# WKUP_j7aen_wkup_ctrl_mmr0_CFG0 register map
Vendor: Texas Instruments
Peripheral module from a debugger description file (folder J722S).
Registers are 32-bit, read-write, reset 0x0 unless marked. A register's access mark holds for its fields unless they carry their own. Offsets are as the file gives them; lines under a group give offsets from that group; [hi:lo] are bit positions; {n}, {i} and the like mark numbered series; 'fields as' and 'values as' point back to an identical list; <NAME> marks a mode.

## WKUP_j7aen_wkup_ctrl_mmr0_CFG0 (part 1 of 3)
{0x7100+4i} CFG0_CLAIMREG_P1_R{i} (i=0..14)
  [31:0] CLAIMREG_P1_R{i} — Claim bits for Partition 1
0x8010 CFG0_WKUP_CLKSEL
  [0] WKUP_CLKSEL_CLK_SEL — Selects Clock Source for Wakeup Domain (Device Manager and Peripherals) Field values (others are reserved): 1'b0 - CPU_MAIN_PLL15_HSDIV2_CLKOUT__PERIPHERALS_ MAIN_PLL15_HSDIV0_CLKOUT undefined - undefined 1'b1 - CPU_AND_PERIPHERALS_MCU_PLL0_HSDIV0_CLKOUT
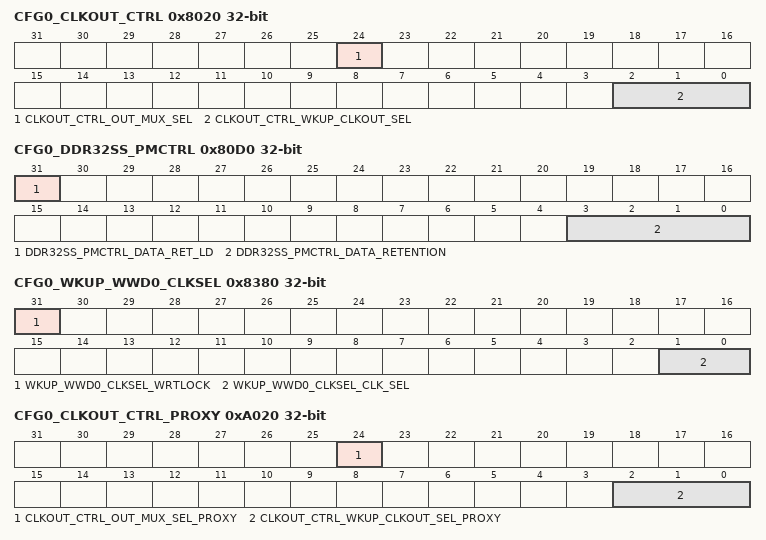
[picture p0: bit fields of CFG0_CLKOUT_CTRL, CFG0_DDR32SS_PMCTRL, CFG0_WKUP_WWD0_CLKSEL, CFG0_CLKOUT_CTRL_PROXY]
0x8020 CFG0_CLKOUT_CTRL
  [24] CLKOUT_CTRL_OUT_MUX_SEL — WKUP CLKOUT (Pin) pin output mux selection. HFOSC0_CLK is a direct output from the HFOSC0 Field values (others are reserved): 1'b0 - CLK_DIV_OUT 1'b1 - HFOSC0_CLK (clk_sel must be DRIVE_LOW)
  [2:0] CLKOUT_CTRL_WKUP_CLKOUT_SEL — Controls WKUP CLKOUT MUX for WKUP_CLKOUT0 Pin Field values (others are reserved): undefined - undefined 3'b000 - DRIVE_LOW 3'b001 - LFOSC0_CLKOUT 3'b010 - MAIN_PLL0_HSDIV2_CLKOUT 3'b011 - MAIN_PLL1_HSDIV2_CLKOUT 3'b100 - MAIN_PLL2_HSDIV9_CLKOUT 3'b101 - DEVICE_CLKOUT_32K 3'b110 - CLK_12M_RC 3'b111 - HFOSC0_CLKOUT
0x8030 CFG0_WKUP_GTC_CLKSEL reset 0x1
  [2:0] WKUP_GTC_CLKSEL_CLK_SEL — Selects the GTC timebase clock source Field values (others are reserved): 3'b000 - MAIN_PLL2_HSDIV5_CLKOUT 3'b001 - MAIN_PLL0_HSDIV6_CLKOUT 3'b010 - CP_GEMAC_CPTS0_RFT_CLK (Pin) 3'b011 - Reserved '0' 3'b100 - MCU_EXT_REFCLK0 (Pin) 3'b101 - EXT_REFCLK1 (Pin) 3'b110 - MCU_SYSCLK0_DIV2 undefined - undefined 3'b111 - MAIN_SYSCLK0
0x803C CFG0_EFUSE_CLKSEL
  [0] EFUSE_CLKSEL_CLK_SEL — Selects the clock source Field values (others are reserved): 1'b0 - HFOSC0_CLKOUT 1'b1 - MAIN_SYSCLK0/16
0x80D0 CFG0_DDR32SS_PMCTRL
  [31] DDR32SS_PMCTRL_DATA_RET_LD — Controls latching of the retention value Field values (others are reserved): 1'b0 - LATCH_CLOSED 1'b1 - LATCH_OPEN
  [3:0] DDR32SS_PMCTRL_DATA_RETENTION — DDR32SS Retention: This is a fault tolerant bit field 0x06 Asserts DDRSS 'data_retention' which will Hi-Z most of the phy output pins except for CKE/RESET# All others (Default 0) : data_retention is deasserted for normal DDR32SS Operation Field values (others are reserved): 4'b0000 - RETENTION_DEACTIVATED 4'b0110 - RETENTION_ACTIVATED
0x8190 CFG0_USB0_CLKSEL
  [0] USB0_CLKSEL_REFCLK_SEL — Selects the clock source for the USB0 ref_clk. Field values (others are reserved): 1'b0 - HFOSC0_CLKOUT 1'b1 - MAIN_PLL0_HSDIV8_CLKOUT
0x8194 CFG0_USB1_CLKSEL
  [0] USB1_CLKSEL_REFCLK_SEL — Selects the clock source for the USB1 ref_clk. Field values (others are reserved): 1'b0 - HFOSC0_CLKOUT 1'b1 - MAIN_PLL0_HSDIV8_CLKOUT
0x81B0 CFG0_WKUP_TIMER0_CLKSEL
  [2:0] WKUP_TIMER0_CLKSEL_CLK_SEL — Timer functional clock input select mux control Field values (others are reserved): 3'b000 - HFOSC0_CLKOUT 3'b001 - DM_CLK/2 undefined - undefined 3'b010 - CLK_12M_RC 3'b011 - MCU_PLL0_HSDIV5_CLKOUT 3'b100 - MCU_EXT_REFCLK0 (Pin) 3'b101 - DEVICE_CLKOUT_32K 3'b110 - CPSW0_CPTS_GENF0 3'b111 - CLK_32K_RC
0x81B4 CFG0_WKUP_TIMER1_CLKSEL
  [2:0] WKUP_TIMER1_CLKSEL_CLK_SEL — Timer functional clock input select mux control Field values (others are reserved): 3'b000 - HFOSC0_CLKOUT 3'b001 - DM_CLK/2 undefined - undefined 3'b010 - CLK_12M_RC 3'b011 - MCU_PLL0_HSDIV5_CLKOUT 3'b100 - MCU_EXT_REFCLK0 (Pin) 3'b101 - DEVICE_CLKOUT_32K 3'b110 - CPSW0_CPTS_GENF0 3'b111 - CLK_32K_RC
0x8340 CFG0_WKUP_WWD0_CTRL
  [3:0] WKUP_WWD0_CTRL_WWD_STOP — Controls Clocks to the WWD Watchdog Counter Field values (others are reserved): 4'b0000 - WWD Counter Running 4'b1010 - WWD Counter Stopped
0x8380 CFG0_WKUP_WWD0_CLKSEL
  [31] WKUP_WWD0_CLKSEL_WRTLOCK — When set, locks WKUP_WWD0_CLKSEL from further writes until the next module reset. Field values (others are reserved): 1'b0 - UNLOCKED 1'b1 - LOCKED
  [1:0] WKUP_WWD0_CLKSEL_CLK_SEL — Windowed watchdog timer functional clock input select mux control Field values (others are reserved): 2'b00 - HFOSC0_CLKOUT 2'b01 - DEVICE_CLKOUT_32K 2'b10 - CLK_12M_RC 2'b11 - CLK_32K
0x8600 CFG0_WKUP_RTC_CLKSEL
  [0] WKUP_RTC_CLKSEL_CLK_SEL — Selects the source of the RTC functional clock Field values (others are reserved): 1'b0 - DEVICE_CLKOUT_32K 1'b1 - CLK_32K_RC
{0x9100+4i} CFG0_CLAIMREG_P2_R{i}_READONLY ro (i=0..12)
  [31:0] CLAIMREG_P2_R{i}_READONLY — Claim bits for Partition 2
0xA010 CFG0_WKUP_CLKSEL_PROXY
  [0] WKUP_CLKSEL_CLK_SEL_PROXY — Selects Clock Source for Wakeup Domain (Device Manager and Peripherals) Field values (others are reserved): 1'b0 - CPU_MAIN_PLL15_HSDIV2_CLKOUT__PERIPHERALS_ MAIN_PLL15_HSDIV0_CLKOUT undefined - undefined 1'b1 - CPU_AND_PERIPHERALS_MCU_PLL0_HSDIV0_CLKOUT
0xA020 CFG0_CLKOUT_CTRL_PROXY
  [24] CLKOUT_CTRL_OUT_MUX_SEL_PROXY — WKUP CLKOUT (Pin) pin output mux selection. HFOSC0_CLK is a direct output from the HFOSC0 Field values (others are reserved): 1'b0 - CLK_DIV_OUT 1'b1 - HFOSC0_CLK (clk_sel must be DRIVE_LOW)
  [2:0] CLKOUT_CTRL_WKUP_CLKOUT_SEL_PROXY — Controls WKUP CLKOUT MUX for WKUP_CLKOUT0 Pin Field values (others are reserved): undefined - undefined 3'b000 - DRIVE_LOW 3'b001 - LFOSC0_CLKOUT 3'b010 - MAIN_PLL0_HSDIV2_CLKOUT 3'b011 - MAIN_PLL1_HSDIV2_CLKOUT 3'b100 - MAIN_PLL2_HSDIV9_CLKOUT 3'b101 - DEVICE_CLKOUT_32K 3'b110 - CLK_12M_RC 3'b111 - HFOSC0_CLKOUT
0xA030 CFG0_WKUP_GTC_CLKSEL_PROXY reset 0x1
  [2:0] WKUP_GTC_CLKSEL_CLK_SEL_PROXY — Selects the GTC timebase clock source Field values (others are reserved): 3'b000 - MAIN_PLL2_HSDIV5_CLKOUT 3'b001 - MAIN_PLL0_HSDIV6_CLKOUT 3'b010 - CP_GEMAC_CPTS0_RFT_CLK (Pin) 3'b011 - Reserved '0' 3'b100 - MCU_EXT_REFCLK0 (Pin) 3'b101 - EXT_REFCLK1 (Pin) 3'b110 - MCU_SYSCLK0_DIV2 undefined - undefined 3'b111 - MAIN_SYSCLK0
0xA03C CFG0_EFUSE_CLKSEL_PROXY
  [0] EFUSE_CLKSEL_CLK_SEL_PROXY — Selects the clock source Field values (others are reserved): 1'b0 - HFOSC0_CLKOUT 1'b1 - MAIN_SYSCLK0/16
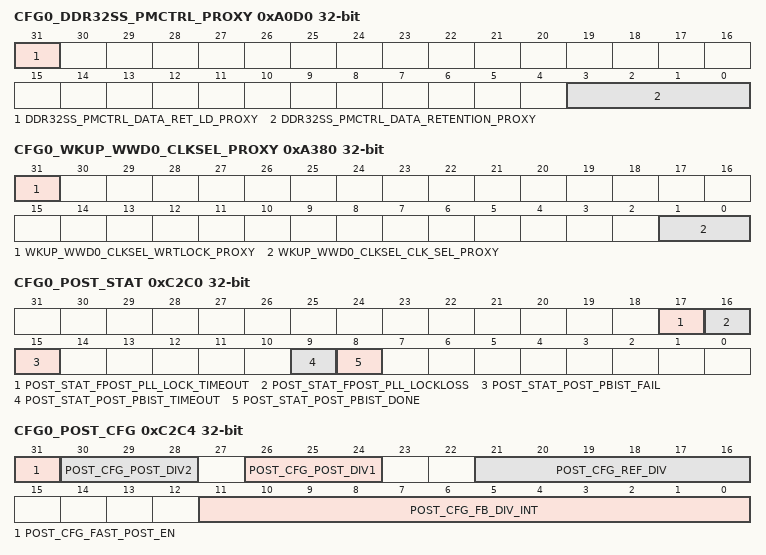
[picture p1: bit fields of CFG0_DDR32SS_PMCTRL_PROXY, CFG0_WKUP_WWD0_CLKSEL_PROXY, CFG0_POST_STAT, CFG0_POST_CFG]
0xA0D0 CFG0_DDR32SS_PMCTRL_PROXY
  [31] DDR32SS_PMCTRL_DATA_RET_LD_PROXY — Controls latching of the retention value Field values (others are reserved): 1'b0 - LATCH_CLOSED 1'b1 - LATCH_OPEN
  [3:0] DDR32SS_PMCTRL_DATA_RETENTION_PROXY — DDR32SS Retention: This is a fault tolerant bit field 0x06 Asserts DDRSS 'data_retention' which will Hi-Z most of the phy output pins except for CKE/RESET# All others (Default 0) : data_retention is deasserted for normal DDR32SS Operation Field values (others are reserved): 4'b0000 - RETENTION_DEACTIVATED 4'b0110 - RETENTION_ACTIVATED
0xA190 CFG0_USB0_CLKSEL_PROXY
  [0] USB0_CLKSEL_REFCLK_SEL_PROXY — Selects the clock source for the USB0 ref_clk. Field values (others are reserved): 1'b0 - HFOSC0_CLKOUT 1'b1 - MAIN_PLL0_HSDIV8_CLKOUT
0xA194 CFG0_USB1_CLKSEL_PROXY
  [0] USB1_CLKSEL_REFCLK_SEL_PROXY — Selects the clock source for the USB1 ref_clk. Field values (others are reserved): 1'b0 - HFOSC0_CLKOUT 1'b1 - MAIN_PLL0_HSDIV8_CLKOUT
0xA1B0 CFG0_WKUP_TIMER0_CLKSEL_PROXY
  [2:0] WKUP_TIMER0_CLKSEL_CLK_SEL_PROXY — Timer functional clock input select mux control Field values (others are reserved): 3'b000 - HFOSC0_CLKOUT 3'b001 - DM_CLK/2 undefined - undefined 3'b010 - CLK_12M_RC 3'b011 - MCU_PLL0_HSDIV5_CLKOUT 3'b100 - MCU_EXT_REFCLK0 (Pin) 3'b101 - DEVICE_CLKOUT_32K 3'b110 - CPSW0_CPTS_GENF0 3'b111 - CLK_32K_RC
0xA1B4 CFG0_WKUP_TIMER1_CLKSEL_PROXY
  [2:0] WKUP_TIMER1_CLKSEL_CLK_SEL_PROXY — Timer functional clock input select mux control Field values (others are reserved): 3'b000 - HFOSC0_CLKOUT 3'b001 - DM_CLK/2 undefined - undefined 3'b010 - CLK_12M_RC 3'b011 - MCU_PLL0_HSDIV5_CLKOUT 3'b100 - MCU_EXT_REFCLK0 (Pin) 3'b101 - DEVICE_CLKOUT_32K 3'b110 - CPSW0_CPTS_GENF0 3'b111 - CLK_32K_RC
0xA340 CFG0_WKUP_WWD0_CTRL_PROXY
  [3:0] WKUP_WWD0_CTRL_WWD_STOP_PROXY — Controls Clocks to the WWD Watchdog Counter Field values (others are reserved): 4'b0000 - WWD Counter Running 4'b1010 - WWD Counter Stopped
0xA380 CFG0_WKUP_WWD0_CLKSEL_PROXY
  [31] WKUP_WWD0_CLKSEL_WRTLOCK_PROXY — When set, locks WKUP_WWD0_CLKSEL from further writes until the next module reset. Field values (others are reserved): 1'b0 - UNLOCKED 1'b1 - LOCKED
  [1:0] WKUP_WWD0_CLKSEL_CLK_SEL_PROXY — Windowed watchdog timer functional clock input select mux control Field values (others are reserved): 2'b00 - HFOSC0_CLKOUT 2'b01 - DEVICE_CLKOUT_32K 2'b10 - CLK_12M_RC 2'b11 - CLK_32K
0xA600 CFG0_WKUP_RTC_CLKSEL_PROXY
  [0] WKUP_RTC_CLKSEL_CLK_SEL_PROXY — Selects the source of the RTC functional clock Field values (others are reserved): 1'b0 - DEVICE_CLKOUT_32K 1'b1 - CLK_32K_RC
{0xB100+4i} CFG0_CLAIMREG_P2_R{i} (i=0..12)
  [31:0] CLAIMREG_P2_R{i} — Claim bits for Partition 2
0xC2C0 CFG0_POST_STAT ro
  [17] POST_STAT_FPOST_PLL_LOCK_TIMEOUT — Differentiates between Fast POST and Slow POST. Fast POST is initiated after the PLL locks using the settings in the POST_CFG MMR. Otherwise, if the PLL lock times out, Slow POST is initated at the PLL reference clock rate. Field values (others are reserved): 1'b0 - FAST_POST 1'b1 - SLOW_POST
  [16] POST_STAT_FPOST_PLL_LOCKLOSS — Indicates that POST exited with a PLL Lockloss Error Field values (others are reserved): 1'b0 - UNKNOWN 1'b1 - EXITED_ON_LOCK_LOSS
  [15] POST_STAT_POST_PBIST_FAIL — POST PBIST failed Field values (others are reserved): 1'b0 - UNKNOWN 1'b1 - FAIL
  [9] POST_STAT_POST_PBIST_TIMEOUT — POST PBIST timed out Field values (others are reserved): 1'b0 - UNKNOWN 1'b1 - TIMEOUT
  [8] POST_STAT_POST_PBIST_DONE — POST PBIST done Field values (others are reserved): 1'b0 - UNKNOWN 1'b1 - DONE
0xC2C4 CFG0_POST_CFG ro
  [31] POST_CFG_FAST_POST_EN — Activate Fast POST mode Field values (others are reserved): 1'b0 - DEACTIVATE 1'b1 - ACTIVATE
  [30:28] POST_CFG_POST_DIV2 — Fast POST PLL secondary post-divider value, must be less than or equal to post_div1. Field values (others are reserved): 3'b000 - UNSUPPORTED 3'b001 - DIV1 3'b010 - DIV2 3'b011 - DIV3 3'b100 - DIV4 3'b101 - DIV5 3'b110 - DIV6 3'b111 - DIV7
  [26:24] POST_CFG_POST_DIV1 — Fast POST PLL primary post-divider value, must be greater than or equal to post_div2. Field values (others are reserved): 3'b000 - UNSUPPORTED 3'b001 - DIV1 3'b010 - DIV2 3'b011 - DIV3 3'b100 - DIV4 3'b101 - DIV5 3'b110 - DIV6 3'b111 - DIV7
  [21:16] POST_CFG_REF_DIV — Fast POST PLL reference clock pre-divider value. Field values (others are reserved): 6'b000000 - UNSUPPORTED 6'b000001 - DIV1 6'b000010 - DIV2 6'b000011 - DIV3 6'b000100 - DIV4 6'b000101 - DIV5 6'b000110 - DIV6 6'b000111 - DIV7 6'b001000 - DIV8 6'b001001 - DIV9 6'b001010 - DIV10 6'b001011 - DIV11 6'b001100 - DIV12 6'b001101 - DIV13 6'b001110 - DIV14 6'b001111 - DIV15 6'b010000 - DIV16 6'b010001 - DIV17 6'b010010 - DIV18 6'b010011 - DIV19 6'b010100 - DIV20 6'b010101 - DIV21 6'b010110 - DIV22 6'b010111 - DIV23 6'b011000 - DIV24 6'b011001 - DIV25 6'b011010 - DIV26 6'b011011 - DIV27 6'b011100 - DIV28 6'b011101 - DIV29 6'b011110 - DIV30 6'b011111 - DIV31 6'b100000 - DIV32 6'b100001 - DIV33 6'b100010 - DIV34 6'b100011 - DIV35 6'b100100 - DIV36 6'b100101 - DIV37 6'b100110 - DIV38 6'b100111 - DIV39 6'b101000 - DIV40 6'b101001 - DIV41 6'b101010 - DIV42 6'b101011 - DIV43 6'b101100 - DIV44 6'b101101 - DIV45 6'b101110 - DIV46 6'b101111 - DIV47 6'b110000 - DIV48 6'b110001 - DIV49 6'b110010 - DIV50 6'b110011 - DIV51 6'b110100 - DIV52 6'b110101 - DIV53 6'b110110 - DIV54 6'b110111 - DIV55 6'b111000 - DIV56 6'b111001 - DIV57 6'b111010 - DIV58 6'b111011 - DIV59 6'b111100 - DIV60 6'b111101 - DIV61 6'b111110 - DIV62 6'b111111 - DIV63
  [11:0] POST_CFG_FB_DIV_INT — Fast POST PLL feedback divider (integer portion) value. In Integer mode values of 16 - 3200 (decimal) are supported.
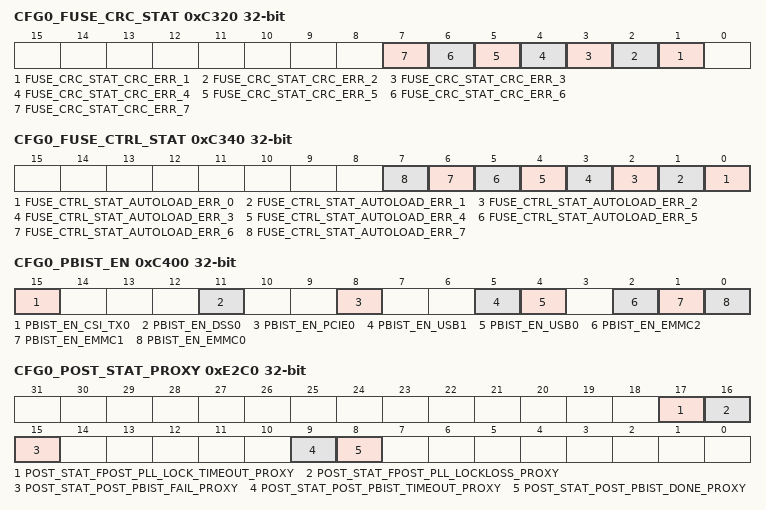
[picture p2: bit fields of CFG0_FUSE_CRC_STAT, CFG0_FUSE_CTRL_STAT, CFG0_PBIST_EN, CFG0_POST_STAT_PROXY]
0xC320 CFG0_FUSE_CRC_STAT ro
  [n] FUSE_CRC_STAT_CRC_ERR_{n} (n=1..7) — Indicates eFuse CRC error on chain {n} Field values (others are reserved): 1'b0 - NO_ERROR 1'b1 - ERROR
0xC340 CFG0_FUSE_CTRL_STAT ro
  [n] FUSE_CTRL_STAT_AUTOLOAD_ERR_{n} (n=0..7) — Autoload Error Status Chain {n} Field values (others are reserved): 1'b0 - NO_ERROR 1'b1 - ERROR
0xC400 CFG0_PBIST_EN
  [15] PBIST_EN_CSI_TX0 — Activates PBIST Access to CSI-TX0 Memories Field values (others are reserved): 1'b0 - DEACTIVATE 1'b1 - ACTIVATE
  [11] PBIST_EN_DSS0 — Activates PBIST Access to DSS0 Memories Field values (others are reserved): 1'b0 - DEACTIVATE 1'b1 - ACTIVATE
  [8] PBIST_EN_PCIE0 — Activates PBIST Access to PCIE0 Memories Field values (others are reserved): 1'b0 - DEACTIVATE 1'b1 - ACTIVATE
  [5] PBIST_EN_USB1 — Activates PBIST Access to USB1 Memories Field values (others are reserved): 1'b0 - DEACTIVATE 1'b1 - ACTIVATE
  [4] PBIST_EN_USB0 — Activates PBIST Access to USB0 Memories Field values (others are reserved): 1'b0 - DEACTIVATE 1'b1 - ACTIVATE
  [2] PBIST_EN_EMMC2 — Activates PBIST Access to MMC2 Memories Field values (others are reserved): 1'b0 - DEACTIVATE 1'b1 - ACTIVATE
  [1] PBIST_EN_EMMC1 — Activates PBIST Access to MMC1 Memories Field values (others are reserved): 1'b0 - DEACTIVATE 1'b1 - ACTIVATE
  [0] PBIST_EN_EMMC0 — Activates PBIST Access to MMC0 Memories Field values (others are reserved): 1'b0 - DEACTIVATE 1'b1 - ACTIVATE
{0xD100+4i} CFG0_CLAIMREG_P3_R{i}_READONLY ro (i=0..8)
  [31:0] CLAIMREG_P3_R{i}_READONLY — Claim bits for Partition 3
0xE2C0 CFG0_POST_STAT_PROXY ro
  [17] POST_STAT_FPOST_PLL_LOCK_TIMEOUT_PROXY — Differentiates between Fast POST and Slow POST. Fast POST is initiated after the PLL locks using the settings in the POST_CFG MMR. Otherwise, if the PLL lock times out, Slow POST is initated at the PLL reference clock rate. Field values (others are reserved): 1'b0 - FAST_POST 1'b1 - SLOW_POST
  [16] POST_STAT_FPOST_PLL_LOCKLOSS_PROXY — Indicates that POST exited with a PLL Lockloss Error Field values (others are reserved): 1'b0 - UNKNOWN 1'b1 - EXITED_ON_LOCK_LOSS
  [15] POST_STAT_POST_PBIST_FAIL_PROXY — POST PBIST failed Field values (others are reserved): 1'b0 - UNKNOWN 1'b1 - FAIL
  [9] POST_STAT_POST_PBIST_TIMEOUT_PROXY — POST PBIST timed out Field values (others are reserved): 1'b0 - UNKNOWN 1'b1 - TIMEOUT
  [8] POST_STAT_POST_PBIST_DONE_PROXY — POST PBIST done Field values (others are reserved): 1'b0 - UNKNOWN 1'b1 - DONE
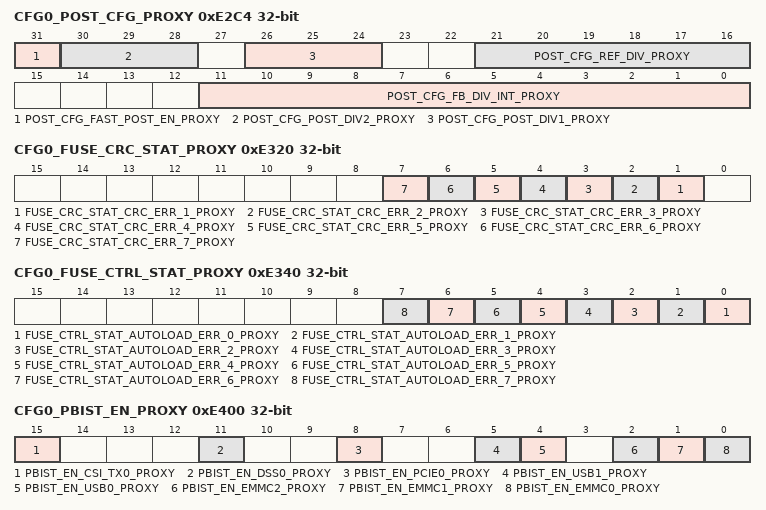
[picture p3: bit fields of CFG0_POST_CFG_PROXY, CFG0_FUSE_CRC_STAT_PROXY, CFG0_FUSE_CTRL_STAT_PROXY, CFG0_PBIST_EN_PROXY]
0xE2C4 CFG0_POST_CFG_PROXY ro
  [31] POST_CFG_FAST_POST_EN_PROXY — Activate Fast POST mode Field values (others are reserved): 1'b0 - DEACTIVATE 1'b1 - ACTIVATE
  [30:28] POST_CFG_POST_DIV2_PROXY — Fast POST PLL secondary post-divider value, must be less than or equal to post_div1. Field values (others are reserved): 3'b000 - UNSUPPORTED 3'b001 - DIV1 3'b010 - DIV2 3'b011 - DIV3 3'b100 - DIV4 3'b101 - DIV5 3'b110 - DIV6 3'b111 - DIV7
  [26:24] POST_CFG_POST_DIV1_PROXY — Fast POST PLL primary post-divider value, must be greater than or equal to post_div2. Field values (others are reserved): 3'b000 - UNSUPPORTED 3'b001 - DIV1 3'b010 - DIV2 3'b011 - DIV3 3'b100 - DIV4 3'b101 - DIV5 3'b110 - DIV6 3'b111 - DIV7
  [21:16] POST_CFG_REF_DIV_PROXY — Fast POST PLL reference clock pre-divider value. Field values (others are reserved): 6'b000000 - UNSUPPORTED 6'b000001 - DIV1 6'b000010 - DIV2 6'b000011 - DIV3 6'b000100 - DIV4 6'b000101 - DIV5 6'b000110 - DIV6 6'b000111 - DIV7 6'b001000 - DIV8 6'b001001 - DIV9 6'b001010 - DIV10 6'b001011 - DIV11 6'b001100 - DIV12 6'b001101 - DIV13 6'b001110 - DIV14 6'b001111 - DIV15 6'b010000 - DIV16 6'b010001 - DIV17 6'b010010 - DIV18 6'b010011 - DIV19 6'b010100 - DIV20 6'b010101 - DIV21 6'b010110 - DIV22 6'b010111 - DIV23 6'b011000 - DIV24 6'b011001 - DIV25 6'b011010 - DIV26 6'b011011 - DIV27 6'b011100 - DIV28 6'b011101 - DIV29 6'b011110 - DIV30 6'b011111 - DIV31 6'b100000 - DIV32 6'b100001 - DIV33 6'b100010 - DIV34 6'b100011 - DIV35 6'b100100 - DIV36 6'b100101 - DIV37 6'b100110 - DIV38 6'b100111 - DIV39 6'b101000 - DIV40 6'b101001 - DIV41 6'b101010 - DIV42 6'b101011 - DIV43 6'b101100 - DIV44 6'b101101 - DIV45 6'b101110 - DIV46 6'b101111 - DIV47 6'b110000 - DIV48 6'b110001 - DIV49 6'b110010 - DIV50 6'b110011 - DIV51 6'b110100 - DIV52 6'b110101 - DIV53 6'b110110 - DIV54 6'b110111 - DIV55 6'b111000 - DIV56 6'b111001 - DIV57 6'b111010 - DIV58 6'b111011 - DIV59 6'b111100 - DIV60 6'b111101 - DIV61 6'b111110 - DIV62 6'b111111 - DIV63
  [11:0] POST_CFG_FB_DIV_INT_PROXY — Fast POST PLL feedback divider (integer portion) value. In Integer mode values of 16 - 3200 (decimal) are supported.
0xE320 CFG0_FUSE_CRC_STAT_PROXY ro
  [n] FUSE_CRC_STAT_CRC_ERR_{n}_PROXY (n=1..7) — Indicates eFuse CRC error on chain {n} Field values (others are reserved): 1'b0 - NO_ERROR 1'b1 - ERROR
0xE340 CFG0_FUSE_CTRL_STAT_PROXY ro
  [n] FUSE_CTRL_STAT_AUTOLOAD_ERR_{n}_PROXY (n=0..7) — Autoload Error Status Chain {n} Field values (others are reserved): 1'b0 - NO_ERROR 1'b1 - ERROR
0xE400 CFG0_PBIST_EN_PROXY
  [15] PBIST_EN_CSI_TX0_PROXY — Activates PBIST Access to CSI-TX0 Memories Field values (others are reserved): 1'b0 - DEACTIVATE 1'b1 - ACTIVATE
  [11] PBIST_EN_DSS0_PROXY — Activates PBIST Access to DSS0 Memories Field values (others are reserved): 1'b0 - DEACTIVATE 1'b1 - ACTIVATE
  [8] PBIST_EN_PCIE0_PROXY — Activates PBIST Access to PCIE0 Memories Field values (others are reserved): 1'b0 - DEACTIVATE 1'b1 - ACTIVATE
  [5] PBIST_EN_USB1_PROXY — Activates PBIST Access to USB1 Memories Field values (others are reserved): 1'b0 - DEACTIVATE 1'b1 - ACTIVATE
  [4] PBIST_EN_USB0_PROXY — Activates PBIST Access to USB0 Memories Field values (others are reserved): 1'b0 - DEACTIVATE 1'b1 - ACTIVATE
  [2] PBIST_EN_EMMC2_PROXY — Activates PBIST Access to MMC2 Memories Field values (others are reserved): 1'b0 - DEACTIVATE 1'b1 - ACTIVATE
  [1] PBIST_EN_EMMC1_PROXY — Activates PBIST Access to MMC1 Memories Field values (others are reserved): 1'b0 - DEACTIVATE 1'b1 - ACTIVATE
  [0] PBIST_EN_EMMC0_PROXY — Activates PBIST Access to MMC0 Memories Field values (others are reserved): 1'b0 - DEACTIVATE 1'b1 - ACTIVATE
{0xF100+4i} CFG0_CLAIMREG_P3_R{i} (i=0..8)
  [31:0] CLAIMREG_P3_R{i} — Claim bits for Partition 3
{0x11100+4i} CFG0_CLAIMREG_P4_R{i}_READONLY ro (i=0..8)
  [31:0] CLAIMREG_P4_R{i}_READONLY — Claim bits for Partition 4
{0x13100+4i} CFG0_CLAIMREG_P4_R{i} (i=0..8)
  [31:0] CLAIMREG_P4_R{i} — Claim bits for Partition 4
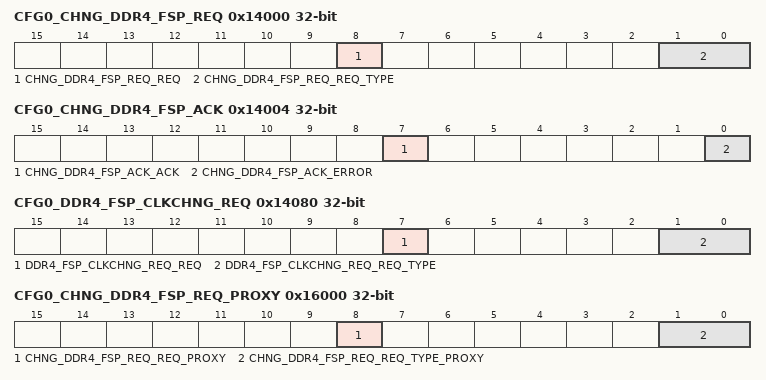
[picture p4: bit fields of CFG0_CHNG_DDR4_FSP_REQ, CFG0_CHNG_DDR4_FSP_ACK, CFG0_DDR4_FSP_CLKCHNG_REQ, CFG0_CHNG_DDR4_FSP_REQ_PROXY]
0x14000 CFG0_CHNG_DDR4_FSP_REQ
  [8] CHNG_DDR4_FSP_REQ_REQ — Initiate FSP frequency change Field values (others are reserved): 1'b0 - INACTIVE 1'b1 - ACTIVE
  [1:0] CHNG_DDR4_FSP_REQ_REQ_TYPE — Frequency request type - Desired Frequency Set Point after switch. Field values (others are reserved): 2'b00 - FSP0 2'b01 - FSP1 2'b10 - FSP2 2'b11 - FSP3
0x14004 CFG0_CHNG_DDR4_FSP_ACK ro
  [7] CHNG_DDR4_FSP_ACK_ACK — Frequency change acknowledge. This bit is only valid when CHNG_DDR4_FSP_REQ_req is active Indication from the DDR Controller that the Frequency Set Point change operation is complete Field values (others are reserved): 1'b0 - IN_PROGRESS 1'b1 - COMPLETE
  [0] CHNG_DDR4_FSP_ACK_ERROR — Frequency change error This bit is only valid when CHNG_DDR4_FSP_REQ_req is active. Field values (others are reserved): 1'b0 - SUCCESS 1'b1 - ERROR
0x14080 CFG0_DDR4_FSP_CLKCHNG_REQ ro
  [7] DDR4_FSP_CLKCHNG_REQ_REQ — DDR Controller FSP clock change request Indicates that the DDR controller needs the DDR clock changed to the frequency set point indicated by the req_type field. This bit is cleared when the DDR4_FSP_CLKCHNG_ACK_ack bit is set. Field values (others are reserved): 1'b0 - INACTIVE 1'b1 - ACTIVE
  [1:0] DDR4_FSP_CLKCHNG_REQ_REQ_TYPE — Frequency request type - Desired Frequency Set Point after switch. Field values (others are reserved): 2'b00 - FSP0 2'b01 - FSP1 2'b10 - FSP2 2'b11 - FSP3
0x140C0 CFG0_DDR4_FSP_CLKCHNG_ACK
  [0] DDR4_FSP_CLKCHNG_ACK_ACK — DDR FSP clock change ackowledge This bit should be set once the DDR clock has been sucessfully changed to the value requested by DDR4_FSP_CLKCHNG_REQ_req_type. Setting this bit will clear the DDR4_FSP_CLKCHNG_REQ_req bit and the associated change request interrupt. Field values (others are reserved): 1'b0 - UNKNOWN (not complete, or not in progress) 1'b1 - COMPLETE
0x15100 CFG0_CLAIMREG_P5_R0_READONLY ro
  [31:0] CLAIMREG_P5_R0_READONLY — Claim bits for Partition 5
0x15104 CFG0_CLAIMREG_P5_R1_READONLY ro
  [31:0] CLAIMREG_P5_R1_READONLY — Claim bits for Partition 5
0x16000 CFG0_CHNG_DDR4_FSP_REQ_PROXY
  [8] CHNG_DDR4_FSP_REQ_REQ_PROXY — Initiate FSP frequency change Field values (others are reserved): 1'b0 - INACTIVE 1'b1 - ACTIVE
  [1:0] CHNG_DDR4_FSP_REQ_REQ_TYPE_PROXY — Frequency request type - Desired Frequency Set Point after switch. Field values (others are reserved): 2'b00 - FSP0 2'b01 - FSP1 2'b10 - FSP2 2'b11 - FSP3
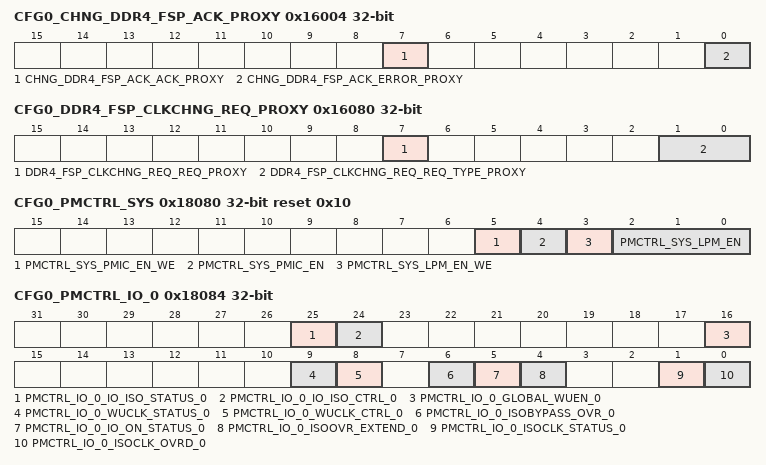
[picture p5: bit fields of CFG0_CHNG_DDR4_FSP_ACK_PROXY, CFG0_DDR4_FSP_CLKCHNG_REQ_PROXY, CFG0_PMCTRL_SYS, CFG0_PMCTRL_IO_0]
0x16004 CFG0_CHNG_DDR4_FSP_ACK_PROXY ro
  [7] CHNG_DDR4_FSP_ACK_ACK_PROXY — Frequency change acknowledge. This bit is only valid when CHNG_DDR4_FSP_REQ_req is active Indication from the DDR Controller that the Frequency Set Point change operation is complete Field values (others are reserved): 1'b0 - IN_PROGRESS 1'b1 - COMPLETE
  [0] CHNG_DDR4_FSP_ACK_ERROR_PROXY — Frequency change error This bit is only valid when CHNG_DDR4_FSP_REQ_req is active. Field values (others are reserved): 1'b0 - SUCCESS 1'b1 - ERROR
0x16080 CFG0_DDR4_FSP_CLKCHNG_REQ_PROXY ro
  [7] DDR4_FSP_CLKCHNG_REQ_REQ_PROXY — DDR Controller FSP clock change request Indicates that the DDR controller needs the DDR clock changed to the frequency set point indicated by the req_type field. This bit is cleared when the DDR4_FSP_CLKCHNG_ACK_ack bit is set. Field values (others are reserved): 1'b0 - INACTIVE 1'b1 - ACTIVE
  [1:0] DDR4_FSP_CLKCHNG_REQ_REQ_TYPE_PROXY — Frequency request type - Desired Frequency Set Point after switch. Field values (others are reserved): 2'b00 - FSP0 2'b01 - FSP1 2'b10 - FSP2 2'b11 - FSP3
0x160C0 CFG0_DDR4_FSP_CLKCHNG_ACK_PROXY
  [0] DDR4_FSP_CLKCHNG_ACK_ACK_PROXY — DDR FSP clock change ackowledge This bit should be set once the DDR clock has been sucessfully changed to the value requested by DDR4_FSP_CLKCHNG_REQ_req_type. Setting this bit will clear the DDR4_FSP_CLKCHNG_REQ_req bit and the associated change request interrupt. Field values (others are reserved): 1'b0 - UNKNOWN (not complete, or not in progress) 1'b1 - COMPLETE
0x17100 CFG0_CLAIMREG_P5_R0
  [31:0] CLAIMREG_P5_R0 — Claim bits for Partition 5
0x17104 CFG0_CLAIMREG_P5_R1
  [31:0] CLAIMREG_P5_R1 — Claim bits for Partition 5
0x18040 CFG0_FW_CTRL_OUT0
  [31:0] FW_CTRL_OUT0_FW_CTRL_OUT0 — Unused
0x18044 CFG0_FW_CTRL_OUT0_SET access not given reset not defined
0x18048 CFG0_FW_CTRL_OUT0_CLR access not given reset not defined
0x1804C CFG0_FW_STS_IN0 access not given reset not defined
0x18050 CFG0_FW_CTRL_OUT1 access not given reset not defined
0x18054 CFG0_FW_CTRL_OUT1_SET access not given reset not defined
0x18058 CFG0_FW_CTRL_OUT1_CLR access not given reset not defined
0x1805C CFG0_FW_STS_IN1 access not given reset not defined
0x18080 CFG0_PMCTRL_SYS reset 0x10
  [5] PMCTRL_SYS_PMIC_EN_WE — Unused Field - Value is Don't Care
  [4] PMCTRL_SYS_PMIC_EN — Controls state of PMIC_LPM_EN_OUT when LPM_EN[2:0] is 000
  [3] PMCTRL_SYS_LPM_EN_WE — Unused Field - Value is Don't Care
  [2:0] PMCTRL_SYS_LPM_EN — Controls whether PMIC_LPM_EN_OUT is driven by the pmic_en bit, or by deep sleep logic. Field values (others are reserved): 3'b000 - PMIC_LPM_EN_OUT controlled by pmic_en bit. 3'b101 - PMIC_LPM_EN_OUT controlled by DeepSleep Logic
0x18084 CFG0_PMCTRL_IO_0 access per field
  [25] PMCTRL_IO_0_IO_ISO_STATUS_0 ro — IO ISO Status. Read 0: IO isolation not active. Read 1: IO isolation active. Reflects value of DM input port io_isoack coming back from IO pad ring.
  [24] PMCTRL_IO_0_IO_ISO_CTRL_0 rw — IO ISO control. Writing this bit to 1 will kick off IO isolation.
  [16] PMCTRL_IO_0_GLOBAL_WUEN_0 rw — Global IO wakeup activate. This is a gating condition to all individual IO WUEN coming from control module. Gating is done in the Spinner logic. 0:All individual IO WUEN are gated in the Spinner logic (override to 0). 1: All individual IO WUEN from control module are going to Ios. Map to DM input port io_globalwkupen
  [9] PMCTRL_IO_0_WUCLK_STATUS_0 ro — Reflects value of DM input port io_wuclkack coming back from IO pad ring.
  [8] PMCTRL_IO_0_WUCLK_CTRL_0 rw — Direct control on WUCLKIN signal to IO pad ring.0:WUCLKIN signal is driven to 0.IO wakeup daisy chain is functional as well as IO whose wakeup feature is activated. 1:WUCLKIN signal is driven to 1. IO wakeup daisy chain is reset and is latching current pad states and WUEN inputs.
  [6] PMCTRL_IO_0_ISOBYPASS_OVR_0 rw — This MMR bit drives directly DM output port io_isobypassundefined.
  [5] PMCTRL_IO_0_IO_ON_STATUS_0 ro — Gives the functional status of the IO ring. Read 0: Part or all of the Ios are not in the ON state that is are in isolation state. Read 1: All Ios are in the ON state. io_on_status = assign 1 if (io_iso == 0 & io_isoack==0 & io_iso_clk == 0 & io_isoclk_ack = 0 ) else 0;
  [4] PMCTRL_IO_0_ISOOVR_EXTEND_0 rw — This drives the SOC chain ISO-OVERRIDE global control. This bit drives directly the DM output port io_isoovrundefined. At the SOC level it is used to activate when 1 or gate-off when 0, the individual ISOOR for each IO. This operates as a global activate/disable for the individual IOs.Control for IO isolation extension. '0' IO isolation is not extended. Transition happens as soon as automatic restore is completed. '1' IO isolation is extended. The IOs whose ISOOVR bits have been individually set in their PADCFG MMRs will all get its IO isolation extended beyond the point when the initial IO daisy chain isolation is released.
  [1] PMCTRL_IO_0_ISOCLK_STATUS_0 ro — Reflects value of DM input port io_isoclkack coming back from IO pad ring.
  [0] PMCTRL_IO_0_ISOCLK_OVRD_0 rw — Override control on ISOCLKIN signal to IO pad ring. When not overridden this signal is controlled by hardware only. 0 ISOCLKIN signal is not override. 1 ISOCLKIN signal is overridden to active value ('1').
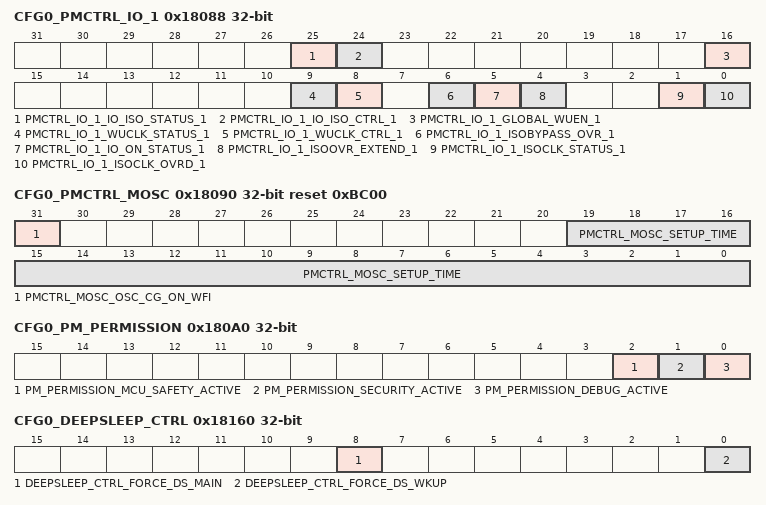
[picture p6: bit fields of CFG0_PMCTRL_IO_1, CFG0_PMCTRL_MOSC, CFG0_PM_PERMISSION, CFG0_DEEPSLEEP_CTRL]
0x18088 CFG0_PMCTRL_IO_1 access per field
  [25] PMCTRL_IO_1_IO_ISO_STATUS_1 ro — IO ISO Status. Read 0: IO isolation not active. Read 1: IO isolation active. Reflects value of DM input port io_isoack coming back from IO pad ring.
  [24] PMCTRL_IO_1_IO_ISO_CTRL_1 rw — IO ISO control. Writing this bit to 1 will kick off IO isolation.
  [16] PMCTRL_IO_1_GLOBAL_WUEN_1 rw — Global IO wakeup activate. This is a gating condition to all individual IO WUEN coming from control module. Gating is done in the Spinner logic. 0:All individual IO WUEN are gated in the Spinner logic (override to 0). 1: All individual IO WUEN from control module are going to Ios. Map to DM input port io_globalwkupen
  [9] PMCTRL_IO_1_WUCLK_STATUS_1 ro — Reflects value of DM input port io_wuclkack coming back from IO pad ring.
  [8] PMCTRL_IO_1_WUCLK_CTRL_1 rw — Direct control on WUCLKIN signal to IO pad ring.0:WUCLKIN signal is driven to 0.IO wakeup daisy chain is functional as well as IO whose wakeup feature is activated. 1:WUCLKIN signal is driven to 1. IO wakeup daisy chain is reset and is latching current pad states and WUEN inputs.
  [6] PMCTRL_IO_1_ISOBYPASS_OVR_1 rw — This MMR bit drives directly DM output port io_isobypassundefined.
  [5] PMCTRL_IO_1_IO_ON_STATUS_1 ro — Gives the functional status of the IO ring. Read 0: Part or all of the Ios are not in the ON state that is are in isolation state. Read 1: All Ios are in the ON state. io_on_status = assign 1 if (io_iso == 0 & io_isoack==0 & io_iso_clk == 0 & io_isoclk_ack = 0 ) else 0;
  [4] PMCTRL_IO_1_ISOOVR_EXTEND_1 rw — This drives the SOC chain ISO-OVERRIDE global control. This bit drives directly the DM output port io_isoovrundefined. At the SOC level it is used to activate when 1 or gate-off when 0, the individual ISOOR for each IO. This operates as a global activate/disable for the individual IOs.Control for IO isolation extension. '0' IO isolation is not extended. Transition happens as soon as automatic restore is completed. '1' IO isolation is extended. The IOs whose ISOOVR bits have been individually set in their PADCFG MMRs will all get its IO isolation extended beyond the point when the initial IO daisy chain isolation is released.
  [1] PMCTRL_IO_1_ISOCLK_STATUS_1 ro — Reflects value of DM input port io_isoclkack coming back from IO pad ring.
  [0] PMCTRL_IO_1_ISOCLK_OVRD_1 rw — Override control on ISOCLKIN signal to IO pad ring. When not overridden this signal is controlled by hardware only. 0 ISOCLKIN signal is not override. 1 ISOCLKIN signal is overridden to active value ('1').
0x18090 CFG0_PMCTRL_MOSC reset 0xBC00
  [31] PMCTRL_MOSC_OSC_CG_ON_WFI — To clock gate the main HFOSC, DM sets this bit then enters the WFI state at which time the HFOSC will be gated. Field values (others are reserved): 1'b0 - INACTIVE 1'b1 - ACTIVE
  [19:0] PMCTRL_MOSC_SETUP_TIME — Number of HFOSC clock cycles before HFOSC clock is ungated to the SOC (allows the HFOSC time to stabilize after starting up, before the SOC is clocked).
0x18098 CFG0_PM_MISC_STATUS ro
  [1:0] PM_MISC_STATUS_OSC_CG_STAT — HFOSC Clock Gating State Field values (others are reserved): 2'b00 - HFOSC_OFF 2'b01 - HFOSC_OFF2ON (transition state) 2'b10 - HFOSC_ON2OFF (transition state) 2'b11 - HFOSC_ON
0x1809C CFG0_PMCTRL_IO_GLB
  [1:0] PMCTRL_IO_GLB_DSEN_QUALIFIED — Bit 0 puts WKUP Domain IOs in Deepsleep. Bit 1 Puts Main Domain IOs in Deepsleep. Field values (others are reserved): 2'b00 - IO_ACTIVE_ALL 2'b01 - IO_DEEPSLEEP_WKUP 2'b10 - IO_DEEPSLEEP_MAIN 2'b11 - IO_DEEPSLEEP_MAIN_AND_WKUP
0x180A0 CFG0_PM_PERMISSION ro
  [2] PM_PERMISSION_MCU_SAFETY_ACTIVE — Read Only - Reads return a 1 when MCU RST_MAGIC_WORD is non-zero. When 1, indicates that the MCU is blocking reset and also deep sleep entry. Field values (others are reserved): 1'b0 - DS_ALLOW 1'b1 - DS_BLOCK
  [1] PM_PERMISSION_SECURITY_ACTIVE — Read Only - Reads return the value of SMS security active. When 1, indicates that SMS is blocking deep sleep entry. Field values (others are reserved): 1'b0 - DS_ALLOW 1'b1 - DS_BLOCK
  [0] PM_PERMISSION_DEBUG_ACTIVE — Read Only - Returns a 1 when Debug is blocking deep sleep entry. Field values (others are reserved): 1'b0 - DS_ALLOW 1'b1 - DS_BLOCK
0x18160 CFG0_DEEPSLEEP_CTRL
  [8] DEEPSLEEP_CTRL_FORCE_DS_MAIN — Force all MAIN IOs into deepsleep mode when set Field values (others are reserved): 1'b0 - IO_ACTIVE 1'b1 - IO_DEEPSLEEP
  [0] DEEPSLEEP_CTRL_FORCE_DS_WKUP — Force all WKUP IOs into deepsleep mode when set Field values (others are reserved): 1'b0 - IO_ACTIVE 1'b1 - IO_DEEPSLEEP
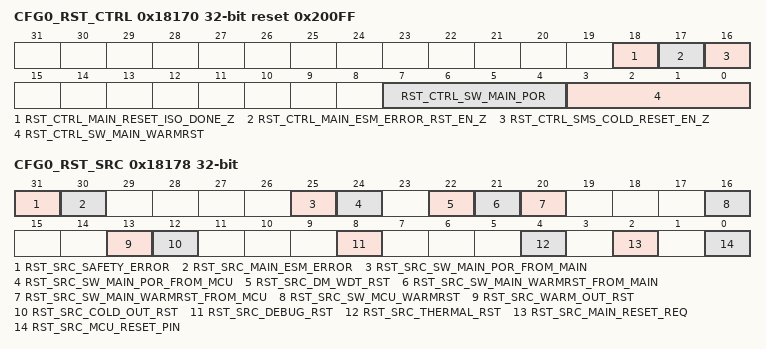
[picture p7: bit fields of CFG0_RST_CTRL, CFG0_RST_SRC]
0x18170 CFG0_RST_CTRL reset 0x200FF
  [18] RST_CTRL_MAIN_RESET_ISO_DONE_Z — Blocks Main Domain Warm Reset. Field values (others are reserved): 1'b0 - PROPOGATE 1'b1 - BLOCK
  [17] RST_CTRL_MAIN_ESM_ERROR_RST_EN_Z — Block Reset of Main by ESM Field values (others are reserved): 1'b0 - PROPOGATE 1'b1 - BLOCK
  [16] RST_CTRL_SMS_COLD_RESET_EN_Z — Block Reset of Main by SMS Field values (others are reserved): 1'b0 - PROPOGATE 1'b1 - BLOCK
  [7:4] RST_CTRL_SW_MAIN_POR — Causes MAIN Domain Power On Reset. This is a fault tolerant bitfield. Automatically resets to 4'b1111 after write. Field values (others are reserved): 4'b0110 - FORCE_RESET 4'b1111 - INACTIVE
  [3:0] RST_CTRL_SW_MAIN_WARMRST — Causes MAIN Domain Warm Reset. This is a fault tolerant bitfield. Automatically resets to 4'b1111 after write. Field values (others are reserved): 4'b0110 - FORCE_RESET 4'b1111 - INACTIVE
0x18174 CFG0_RST_STAT ro
  [0] RST_STAT_MCU_RESET_ISO_DONE_Z — Indicates MCU Domain is in Reset Isolation When Active (Low) Field values (others are reserved): 1'b0 - ISOLATION 1'b1 - PASS_THROUGH
0x18178 CFG0_RST_SRC ro
  [31] RST_SRC_SAFETY_ERROR — Reset Caused by MCU ESM Error. Field values (others are reserved): 1'b0 - UNKNOWN 1'b1 - DETECTED
  [30] RST_SRC_MAIN_ESM_ERROR — Reset Caused by Main ESM Error. Field values (others are reserved): 1'b0 - UNKNOWN 1'b1 - DETECTED
  [25] RST_SRC_SW_MAIN_POR_FROM_MAIN — Software Main Power On Reset From CTRL_MMR0. Field values (others are reserved): 1'b0 - UNKNOWN 1'b1 - DETECTED
  [24] RST_SRC_SW_MAIN_POR_FROM_MCU — Software Main Power On Reset From MCU_CTRL_MMR0. Field values (others are reserved): 1'b0 - UNKNOWN 1'b1 - DETECTED
  [22] RST_SRC_DM_WDT_RST — Watchdog Initiated Reset. Field values (others are reserved): 1'b0 - UNKNOWN 1'b1 - DETECTED
  [21] RST_SRC_SW_MAIN_WARMRST_FROM_MAIN — Software Main Warm Reset From CTRL_MMR0. Field values (others are reserved): 1'b0 - UNKNOWN 1'b1 - DETECTED
  [20] RST_SRC_SW_MAIN_WARMRST_FROM_MCU — Software Main Warm Reset From MCU_CTRL_MMR0. Field values (others are reserved): 1'b0 - UNKNOWN 1'b1 - DETECTED
  [16] RST_SRC_SW_MCU_WARMRST — Software Warm Reset. Field values (others are reserved): 1'b0 - UNKNOWN 1'b1 - DETECTED
  [13] RST_SRC_WARM_OUT_RST — SMS Warm Reset. Field values (others are reserved): 1'b0 - UNKNOWN 1'b1 - DETECTED
  [12] RST_SRC_COLD_OUT_RST — SMS Cold Reset. Field values (others are reserved): 1'b0 - UNKNOWN 1'b1 - DETECTED
  [8] RST_SRC_DEBUG_RST — Debug Subsystem Initiated Reset. Field values (others are reserved): 1'b0 - UNKNOWN 1'b1 - DETECTED
  [4] RST_SRC_THERMAL_RST — Thermal Reset. Field values (others are reserved): 1'b0 - UNKNOWN 1'b1 - DETECTED
  [2] RST_SRC_MAIN_RESET_REQ — Main Reset Pin. Field values (others are reserved): 1'b0 - UNKNOWN 1'b1 - DETECTED
  [0] RST_SRC_MCU_RESET_PIN — Rest Caused by MCU Reset Pin. Field values (others are reserved): 1'b0 - UNKNOWN 1'b1 - DETECTED
0x1817C CFG0_RST_MAGIC_WORD ro
  [31:0] RST_MAGIC_WORD_MCU_MAGIC_WORD — Magic Word Indicating Status of MCU Subsystem Boot
0x18180 CFG0_WKUP0_EN
  [31:0] WKUP0_EN_WKUPEN — Activates Wakeup from on-chip sources. In addition to values listed, any OR combination of the values is also valid. Field values (others are reserved): 32'h00000001 - WKUP_I2C0 32'h00000002 - WKUP_USART0 32'h00000004 - MCU_GPIO0 32'h00000008 - DEBUG undefined - undefined 32'h00000020 - WKUP_TIMER0 32'h00000040 - WKUP_TIMER1 32'h00000080 - WKUP_RTC 32'h00000100 - MAIN_RESET_REQz 32'h00000200 - USB0_IN_BAND 32'h00000400 - USB1_IN_BAND 32'h00010000 - MAIN_IO_DAISY_CHAIN 32'h00020000 - MCU_IO_DAISY_CHAIN 32'h00040000 - CANUART_IO_DAISY_CHAIN
